# MKW21Z4 register map
Vendor: Freescale Semiconductor, Inc.; Series: Kinetis_W; File version: 1.6
CPU: CM0PLUS r0p0, little endian, no MPU, no FPU, VTOR, 2 interrupt priority bits
Registers are 16-bit, read-write, no defined reset value unless marked. A register's access mark holds for its fields unless they carry their own. Offsets are from the block's base; [hi:lo] are bit positions; {n}, {i} and the like mark numbered series; 'fields as' and 'values as' point back to an identical list.

## ZLL_REGS — ZLL
Base 0x4005D000
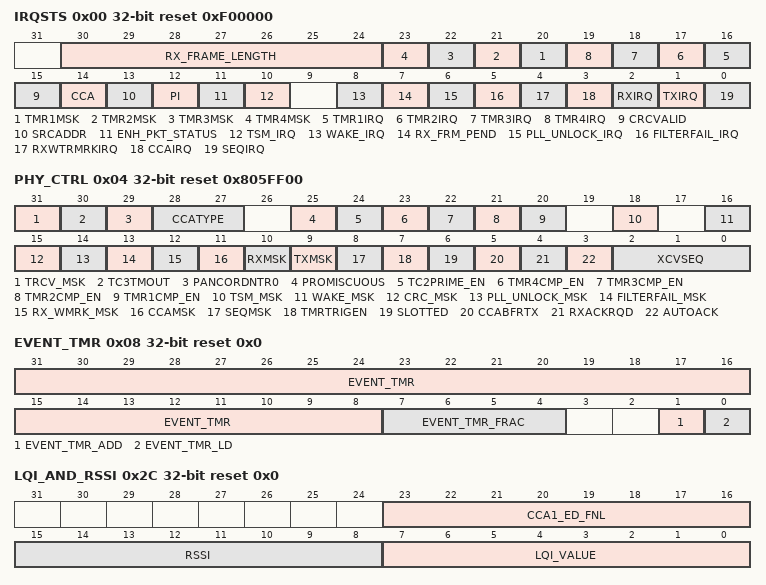
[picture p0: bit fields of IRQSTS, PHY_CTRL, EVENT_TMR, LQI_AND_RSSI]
0x00 IRQSTS 32-bit reset 0xF00000 (reset mask 0x80F00200) — INTERRUPT REQUEST STATUS
  [30:24] RX_FRAME_LENGTH ro — Receive Frame Length
  [n+19] TMR{n}MSK (n=1..4) — Timer Comperator {n} Interrupt Mask bit
    0=allows interrupt when comparator matches event timer count; 1=Interrupt generation is disabled, but a TMR{n}IRQ flag can be set
  [n+15] TMR{n}IRQ (n=1..4) — Timer {n} IRQ
  [15] CRCVALID ro — CRC Valid Status
    0=Rx FCS != calculated CRC (incorrect); 1=Rx FCS = calculated CRC (correct)
  [14] CCA ro — CCA Status
    0=IDLE; 1=BUSY
  [13] SRCADDR ro — Source Address Match Status
  [12] PI ro — Poll Indication
    0=the received packet was not a data request; 1=the received packet was a data request, regardless of whether a Source Address table match occurred, or whether Source Address Management is enabled or not
  [11] ENH_PKT_STATUS ro — Enhanced Packet Status
    0=The last packet received was neither 4e- nor 2015-compliant; 1=The last packet received was 4e- or 2015-compliant (RX_FRAME_FILTER register should be queried for additional status bits)
  [10] TSM_IRQ ro
    0=A TSM Interrupt has not occurred; 1=A TSM Interrupt has occurred
  [8] WAKE_IRQ — WAKE Interrupt Request
    0=A Wake Interrupt has not occurred; 1=A Wake Interrupt has occurred
  [7] RX_FRM_PEND ro — RX Frame Pending
  [6] PLL_UNLOCK_IRQ
    0=A PLL Unlock Interrupt has not occurred; 1=A PLL Unlock Interrupt has occurred
  [5] FILTERFAIL_IRQ
    0=A Filter Fail Interrupt has not occurred; 1=A Filter Fail Interrupt has occurred
  [4] RXWTRMRKIRQ — Receive Watermark IRQ
    0=A Receive Watermark Interrupt has not occurred; 1=A Receive Watermark Interrupt has occurred
  [3] CCAIRQ
    0=A CCA Interrupt has not occurred; 1=A CCA Interrupt has occurred
  [2] RXIRQ
    0=A RX Interrupt has not occurred; 1=A RX Interrupt has occurred
  [1] TXIRQ
    0=A TX Interrupt has not occurred; 1=A TX Interrupt has occurred
  [0] SEQIRQ — Sequencer IRQ
    0=A Sequencer Interrupt has not occurred; 1=A Sequencer Interrupt has occurred
0x04 PHY_CTRL 32-bit reset 0x805FF00 — PHY CONTROL
  [31] TRCV_MSK — Transceiver Global Interrupt Mask
    0=Enable any unmasked interrupt source to assert zigbee interrupt; 1=Mask all interrupt sources from asserting zigbee interrupt
  [30] TC3TMOUT — TMR3 Timeout Enable
    0=TMR3 is a software timer only; 1=Enable TMR3 to abort Rx or CCCA operations
  [29] PANCORDNTR0 — Device is a PAN Coordinator on PAN0
  [28:27] CCATYPE — Clear Channel Assessment Type
    0=ENERGY DETECT; 1=CCA MODE 1; 2=CCA MODE 2; 3=CCA MODE 3
  [25] PROMISCUOUS — Promiscuous Mode Enable
    0=normal mode; 1=all packet filtering except frame length checking (FrameLength>=5 and FrameLength<=127) is bypassed
  [24] TC2PRIME_EN — Timer 2 Prime Compare Enable
    0=Don't allow a match of the lower 16 bits of Event Timer to T2PRIMECMP to set TMR2IRQ; 1=Allow a match of the lower 16 bits of Event Timer to T2PRIMECMP to set TMR2IRQ
  [23] TMR4CMP_EN — Timer 4 Compare Enable
    0=Don't allow an Event Timer Match to T4CMP to set TMR4IRQ; 1=Allow an Event Timer Match to T4CMP to set TMR4IRQ
  [22] TMR3CMP_EN — Timer 3 Compare Enable
    0=Don't allow an Event Timer Match to T3CMP to set TMR3IRQ; 1=Allow an Event Timer Match to T3CMP to set TMR3IRQ
  [21] TMR2CMP_EN — Timer 2 Compare Enable
    0=Don't allow an Event Timer Match to T2CMP or T2PRIMECMP to set TMR2IRQ; 1=Allow an Event Timer Match to T2CMP or T2PRIMECMP to set TMR2IRQ
  [20] TMR1CMP_EN — Timer 1 Compare Enable
    0=Don't allow an Event Timer Match to T1CMP to set TMR1IRQ; 1=Allow an Event Timer Match to T1CMP to set TMR1IRQ
  [18] TSM_MSK
    0=allows assertion of a TSM interrupt to generate a zigbee interrupt; 1=Assertion of a TSM interrupt will set the TSM_IRQ status bit, but a zigbee interrupt is not generated
  [16] WAKE_MSK
    0=Allows a wakeup from DSM to generate a zigbee interrupt; 1=Wakeup from DSM will set the WAKE_IRQ status bit, but a zigbee interrupt is not generated
  [15] CRC_MSK — CRC Mask
    0=sequence manager ignores CRCVALID and considers the receive operation complete after the last octet of the frame has been received; 1=sequence manager requires CRCVALID=1 at the end of the received frame in order for the receive operation to complete successfully; if CRCVALID=0, sequence manager will return to preamble-detect mode after the last octet of the frame has been received
  [14] PLL_UNLOCK_MSK — PLL Unlock Interrupt Mask
    0=allows PLL unlock event to generate a zigbee interrupt; 1=A PLL unlock event will set the PLL_UNLOCK_IRQ status bit, but a zigbee interrupt is not generated
  [13] FILTERFAIL_MSK — FilterFail Interrupt Mask
    0=allows Packet Processor Filtering Failure to generate a zigbee interrupt; 1=A Packet Processor Filtering Failure will set the FILTERFAIL_IRQ status bit, but a zigbee interrupt is not generated
  [12] RX_WMRK_MSK — RX Watermark Interrupt Mask
    0=allows a Received Byte Count match to the RX_WTR_MARK threshold register to generate a zigbee interrupt; 1=A Received Byte Count match to the RX_WTR_MARK threshold register will set the RXWTRMRKIRQ status bit, but a zigbee interrupt is not generated
  [11] CCAMSK — CCA Interrupt Mask
    0=allows completion of a CCA operation to generate a zigbee interrupt; 1=Completion of a CCA operation will set the CCA status bit, but a zigbee interrupt is not generated
  [10] RXMSK — RX Interrupt Mask
    0=allows completion of a RX operation to generate a zigbee interrupt; 1=Completion of a RX operation will set the RXIRQ status bit, but a zigbee interrupt is not generated
  [9] TXMSK — TX Interrupt Mask
    0=allows completion of a TX operation to generate a zigbee interrupt; 1=Completion of a TX operation will set the TXIRQ status bit, but a zigbee interrupt is not generated
  [8] SEQMSK — Sequencer Interrupt Mask
    0=allows completion of an autosequence to generate a zigbee interrupt; 1=Completion of an autosequence will set the SEQIRQ status bit, but a zigbee interrupt is not generated
  [7] TMRTRIGEN — Timer2 Trigger Enable
    0=programmed sequence initiates immediately upon write to XCVSEQ; 1=allow timer TC2 (or TC2') to initiate a preprogrammed sequence (see XCVSEQ register)
  [6] SLOTTED — Slotted Mode
  [5] CCABFRTX — CCA Before TX
    0=no CCA required, transmit operation begins immediately; 1=at least one CCA measurement is required prior to the transmit operation (see also SLOTTED)
  [4] RXACKRQD — Receive Acknowledge Frame required
    0=An ordinary receive frame (any type of frame) follows the transmit frame; 1=A receive Ack frame is expected to follow the transmit frame (non-Ack frames are rejected)
  [3] AUTOACK — Auto Acknowledge Enable
    0=sequence manager will not follow a receive frame with a Tx Ack frame, under any conditions; the autosequence will terminate after the receive frame; 1=sequence manager will follow a receive frame with an automatic hardware-generated Tx Ack frame, assuming other necessary conditions are met
  [2:0] XCVSEQ — Zigbee Transceiver Sequence Selector
    0=I (IDLE); 1=R (RECEIVE); 2=T (TRANSMIT); 3=C (CCA); 4=TR (TRANSMIT/RECEIVE); 5=CCCA (CONTINUOUS CCA)
0x08 EVENT_TMR 32-bit reset 0x0 (reset mask 0xF) — EVENT TIMER
  [31:8] EVENT_TMR — Event Timer Integer Component
  [7:4] EVENT_TMR_FRAC — Event Timer Fractional Component
  [1] EVENT_TMR_ADD wo — Event Timer Add Enable
  [0] EVENT_TMR_LD wo — Event Timer Load Enable
0x0C TIMESTAMP 32-bit ro reset 0x0 (reset mask 0xFF000000)
  [23:0] TIMESTAMP
0x10 T1CMP 32-bit reset 0xFFFFFF — T1 COMPARE
  [23:0] T1CMP — TMR1 Compare Value
0x14 T2CMP 32-bit reset 0xFFFFFF — T2 COMPARE
  [23:0] T2CMP — TMR2 Compare Value
0x18 T2PRIMECMP 32-bit reset 0xFFFF — T2 PRIME COMPARE
  [15:0] T2PRIMECMP — TMR2 Prime Compare Value
0x1C T3CMP 32-bit reset 0xFFFFFF — T3 COMPARE
  [23:0] T3CMP — TMR3 Compare Value
0x20 T4CMP 32-bit reset 0xFFFFFF — T4 COMPARE
  [23:0] T4CMP — TMR4 Compare Value
0x24 PA_PWR 32-bit reset 0x0 — PA POWER
  [5:0] PA_PWR — PA Power
0x28 CHANNEL_NUM0 32-bit reset 0x12 — CHANNEL NUMBER 0
  [6:0] CHANNEL_NUM0 — Channel Number for PAN0
0x2C LQI_AND_RSSI 32-bit ro reset 0x0 (reset mask 0xFF000000)
  [23:16] CCA1_ED_FNL — Final Result for CCA Mode 1 and Energy Detect
  [15:8] RSSI — RSSI Value
  [7:0] LQI_VALUE
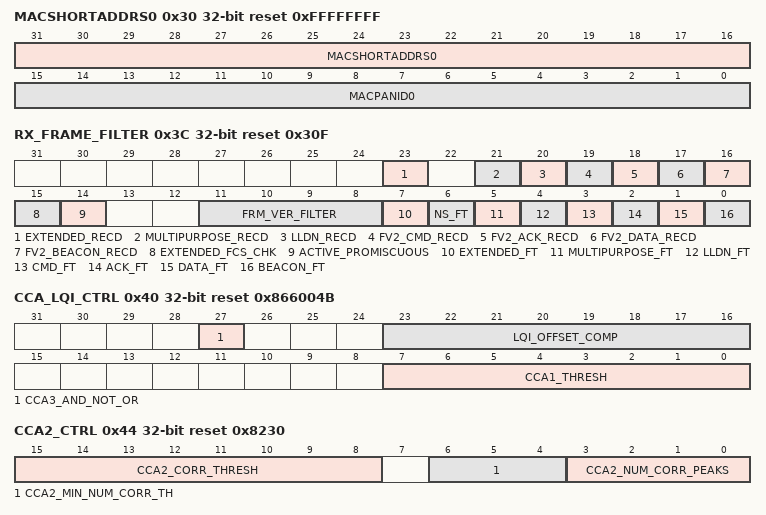
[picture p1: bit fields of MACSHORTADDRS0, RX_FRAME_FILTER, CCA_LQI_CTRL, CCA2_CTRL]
0x30 MACSHORTADDRS0 32-bit reset 0xFFFFFFFF — MAC SHORT ADDRESS 0
  [31:16] MACSHORTADDRS0 — MAC SHORT ADDRESS FOR PAN0
  [15:0] MACPANID0 — MAC PAN ID for PAN0
0x34 MACLONGADDRS0_LSB 32-bit reset 0xFFFFFFFF — MAC LONG ADDRESS 0 LSB
  [31:0] MACLONGADDRS0_LSB — MAC LONG ADDRESS for PAN0 LSB
0x38 MACLONGADDRS0_MSB 32-bit reset 0xFFFFFFFF — MAC LONG ADDRESS 0 MSB
  [31:0] MACLONGADDRS0_MSB — MAC LONG ADDRESS for PAN0 MSB
0x3C RX_FRAME_FILTER 32-bit reset 0x30F (reset mask 0xFF40FFFF) — RECEIVE FRAME FILTER
  [23] EXTENDED_RECD ro — Extended Packet Received
    0=The last packet received was not Frame Type EXTENDED; 1=The last packet received was Frame Type EXTENDED, and EXTENDED_FT=1 to allow such packets
  [21] MULTIPURPOSE_RECD ro — Multipurpose Packet Received
    0=last packet received was not Frame Type MULTIPURPOSE; 1=The last packet received was Frame Type MULTIPURPOSE, and MULTIPURPOSE_FT=1 to allow such packets
  [20] LLDN_RECD ro — LLDN Packet Received
    0=The last packet received was not Frame Type LLDN; 1=The last packet received was Frame Type LLDN, and LLDN_FT=1 to allow such packets
  [19] FV2_CMD_RECD ro — Frame Version 2 MAC Command Packet Received
    0=The last packet received was not Frame Type MAC Command with Frame Version 2; 1=The last packet received was Frame Type MAC Command with Frame Version 2, and FRM_VER_FILTER[2]=1 to allow such packets
  [18] FV2_ACK_RECD ro — Frame Version 2 Acknowledge Packet Received
    0=The last packet received was not Frame Type Ack with Frame Version 2; 1=The last packet received was Frame Type Ack with Frame Version 2, and FRM_VER_FILTER[2]=1 to allow such packets
  [17] FV2_DATA_RECD ro — Frame Version 2 Data Packet Received
    0=The last packet received was not Frame Type Data with Frame Version 2; 1=The last packet received was Frame Type Data with Frame Version 2, and FRM_VER_FILTER[2]=1 to allow such packets
  [16] FV2_BEACON_RECD ro — Frame Version 2 Beacon Packet Received
    0=The last packet received was not Frame Type Beacon with Frame Version 2; 1=The last packet received was Frame Type Beacon with Frame Version 2, and FRM_VER_FILTER[2]=1 to allow such packets
  [15] EXTENDED_FCS_CHK — Verify FCS on Frame Type Extended
    0=Packet Processor will not check FCS for Frame Type EXTENDED (default); 1=Packet Processor will check FCS at end-of-packet based on packet length derived from PHR, for Frame Type EXTENDED
  [14] ACTIVE_PROMISCUOUS
    0=normal operation; 1=Provide Data Indication on all received packets under the same rules which apply in PROMISCUOUS mode, however acknowledge those packets under rules which apply in non-PROMISCUOUS mode
  [11:8] FRM_VER_FILTER — Frame Version selector.
  [7] EXTENDED_FT — Extended Frame Type Enable
    0=reject all Extended frames; 1=Extended frame type enabled (Frame Type 7)
  [6] NS_FT — "Not Specified" Frame Type Enable
    0=reject all "Not Specified" frames; 1=Not-specified (reserved) frame type enabled. Applies to Frame Type 6. No packet filtering is performed, except for frame length checking (FrameLength>=5 and FrameLength<=127). No AUTOACK is transmitted for this Frame Type
  [5] MULTIPURPOSE_FT — Multipurpose Frame Type Enable
    0=reject all Multipurpose frames; 1=Multipurpose frame type enabled (Frame Type 5)
  [4] LLDN_FT — LLDN Frame Type Enable
    0=reject all LLDN frames; 1=LLDN frame type enabled (Frame Type 4)
  [3] CMD_FT — MAC Command Frame Type Enable
    0=reject all MAC Command frames; 1=MAC Command frame type enabled
  [2] ACK_FT — Ack Frame Type Enable
    0=reject all Acknowledge frames; 1=Acknowledge frame type enabled
  [1] DATA_FT — Data Frame Type Enable
    0=reject all Beacon frames; 1=Data frame type enabled
  [0] BEACON_FT — Beacon Frame Type Enable
    0=reject all Beacon frames; 1=Beacon frame type enabled
0x40 CCA_LQI_CTRL 32-bit reset 0x866004B — CCA AND LQI CONTROL
  [27] CCA3_AND_NOT_OR — CCA Mode 3 AND not OR
    0=CCA1 or CCA2; 1=CCA1 and CCA2
  [23:16] LQI_OFFSET_COMP — LQI Offset Compensation
  [7:0] CCA1_THRESH — CCA Mode 1 Threshold
0x44 CCA2_CTRL 32-bit reset 0x8230 (reset mask 0xFFFFFFF0) — CCA2 CONTROL
  [15:8] CCA2_CORR_THRESH — CCA Mode 2 Correlation Threshold
  [6:4] CCA2_MIN_NUM_CORR_TH — CCA Mode 2 Threshold Number of Correlation Peaks
  [3:0] CCA2_NUM_CORR_PEAKS ro — CCA Mode 2 Number of Correlation Peaks Detected
0x4C DSM_CTRL 32-bit reset 0x0 — DSM CONTROL
  [0] ZIGBEE_SLEEP_EN — Zigbee sleep enable
0x50 BSM_CTRL 32-bit reset 0x0 — BSM CONTROL
  [0] BSM_EN — BSM Enable
    0=Zigbee Bit Streaming Mode Disabled; 1=Zigbee Bit Streaming Mode Enabled
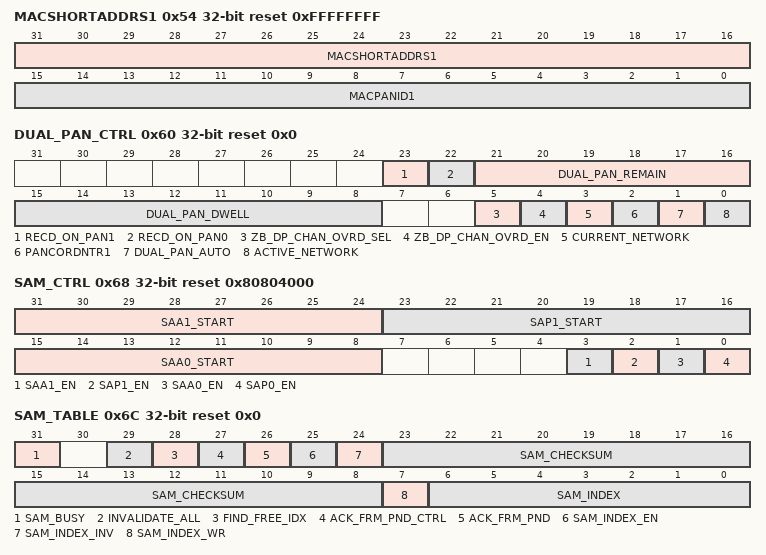
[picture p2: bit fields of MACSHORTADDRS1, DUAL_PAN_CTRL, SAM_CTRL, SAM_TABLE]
0x54 MACSHORTADDRS1 32-bit reset 0xFFFFFFFF — MAC SHORT ADDRESS FOR PAN1
  [31:16] MACSHORTADDRS1 — MAC SHORT ADDRESS for PAN1
  [15:0] MACPANID1 — MAC PAN ID for PAN1
0x58 MACLONGADDRS1_LSB 32-bit reset 0xFFFFFFFF — MAC LONG ADDRESS 1 LSB
  [31:0] MACLONGADDRS1_LSB — MAC LONG ADDRESS for PAN1 LSB
0x5C MACLONGADDRS1_MSB 32-bit reset 0xFFFFFFFF — MAC LONG ADDRESS 1 MSB
  [31:0] MACLONGADDRS1_MSB — MAC LONG ADDRESS for PAN1 MSB
0x60 DUAL_PAN_CTRL 32-bit reset 0x0 (reset mask 0xFF00FFF7) — DUAL PAN CONTROL
  [23] RECD_ON_PAN1 ro — Last Packet was Received on PAN1
  [22] RECD_ON_PAN0 ro — Last Packet was Received on PAN0
  [21:16] DUAL_PAN_REMAIN ro — Time Remaining before next PAN switch in auto Dual PAN mode
  [15:8] DUAL_PAN_DWELL — Dual PAN Channel Frequency Dwell Time
  [5] ZB_DP_CHAN_OVRD_SEL — Dual PAN Channel Override Selector
  [4] ZB_DP_CHAN_OVRD_EN — Dual PAN Channel Override Enable
  [3] CURRENT_NETWORK ro — Indicates which PAN is currently selected by hardware
    0=PAN0 is selected; 1=PAN1 is selected
  [2] PANCORDNTR1 — Device is a PAN Coordinator on PAN1
  [1] DUAL_PAN_AUTO — Activates automatic Dual PAN operating mode
  [0] ACTIVE_NETWORK — Active Network Selector
    0=Select PAN0; 1=Select PAN1
0x64 CHANNEL_NUM1 32-bit reset 0x7F — CHANNEL NUMBER 1
  [6:0] CHANNEL_NUM1 — Channel Number for PAN1
0x68 SAM_CTRL 32-bit reset 0x80804000 — SAM CONTROL
  [31:24] SAA1_START — First Index of SAA1 partition
  [23:16] SAP1_START — First Index of SAP1 partition
  [15:8] SAA0_START — First Index of SAA0 partition
  [3] SAA1_EN — Enables SAA1 Partition of the SAM Table
    0=Disables SAA1 Partition; 1=Enables SAA1 Partition
  [2] SAP1_EN — Enables SAP1 Partition of the SAM Table
    0=Disables SAP1 Partition; 1=Enables SAP1 Partition
  [1] SAA0_EN — Enables SAA0 Partition of the SAM Table
    0=Disables SAA0 Partition; 1=Enables SAA0 Partition
  [0] SAP0_EN — Enables SAP0 Partition of the SAM Table
    0=Disables SAP0 Partition; 1=Enables SAP0 Partition
0x6C SAM_TABLE 32-bit reset 0x0 (reset mask 0x4C00007F) — SOURCE ADDRESS MANAGEMENT TABLE
  [31] SAM_BUSY ro — SAM Table Update Status Bit
  [29] INVALIDATE_ALL wo — Invalidate Entire SAM Table
  [28] FIND_FREE_IDX wo — Find First Free Index
  [27] ACK_FRM_PND_CTRL — Manual Control for AutoTxAck FramePending field
    0=the FramePending field of the Frame Control Field of the next automatic TX acknowledge packet is determined by hardware; 1=the FramePending field of the Frame Control Field of the next automatic TX acknowledge packet tracks ACK_FRM_PEND
  [26] ACK_FRM_PND — State of AutoTxAck FramePending field when SAM Accelleration is Disabled
  [25] SAM_INDEX_EN wo — Enable the SAM table index selected by SAM_INDEX
  [24] SAM_INDEX_INV wo — Invalidate the SAM table index selected by SAM_INDEX
  [23:8] SAM_CHECKSUM — Software-computed source address checksum, to be installed into a table index
  [7] SAM_INDEX_WR wo — Enables SAM Table Contents to be updated
  [6:0] SAM_INDEX — Contains the SAM table index to be enabled or invalidated
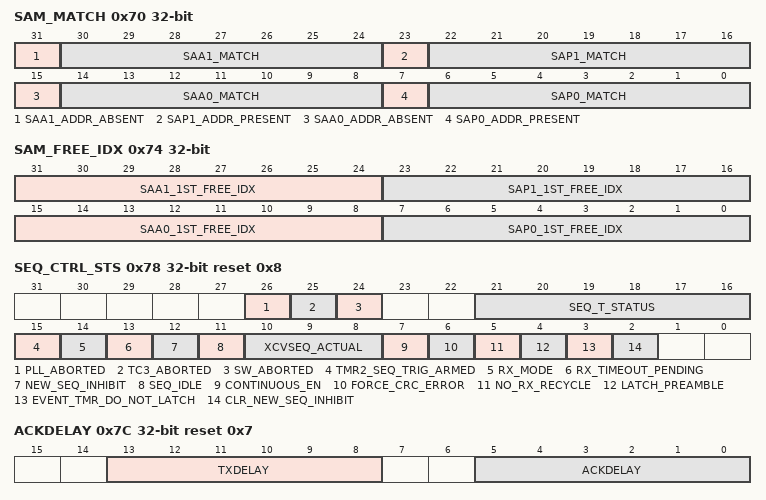
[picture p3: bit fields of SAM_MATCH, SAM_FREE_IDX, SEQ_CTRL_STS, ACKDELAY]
0x70 SAM_MATCH 32-bit ro — SOURCE ADDRESS MANAGEMENT MATCH
  [31] SAA1_ADDR_ABSENT — A Checksum Match is Absent in the SAP1 Partition of the SAM Table
  [30:24] SAA1_MATCH — Index in the SAA1 Partition of the SAM Table corresponding to the first checksum match
  [23] SAP1_ADDR_PRESENT — A Checksum Match is Present in the SAP1 Partition of the SAM Table
  [22:16] SAP1_MATCH — Index in the SAP1 Partition of the SAM Table corresponding to the first checksum match
  [15] SAA0_ADDR_ABSENT — A Checksum Match is Absent in the SAA0 Partition of the SAM Table
  [14:8] SAA0_MATCH — Index in the SAA0 Partition of the SAM Table corresponding to the first checksum match
  [7] SAP0_ADDR_PRESENT — A Checksum Match is Present in the SAP0 Partition of the SAM Table
  [6:0] SAP0_MATCH — Index in the SAP0 Partition of the SAM Table corresponding to the first checksum match
0x74 SAM_FREE_IDX 32-bit ro — SAM FREE INDEX
  [31:24] SAA1_1ST_FREE_IDX — First non-enabled (invalid) index in the SAA1 partition
  [23:16] SAP1_1ST_FREE_IDX — First non-enabled (invalid) index in the SAP1 partition
  [15:8] SAA0_1ST_FREE_IDX — First non-enabled (invalid) index in the SAA0 partition
  [7:0] SAP0_1ST_FREE_IDX — First non-enabled (invalid) index in the SAP0 partition
0x78 SEQ_CTRL_STS 32-bit reset 0x8 (reset mask 0xF8C000FF) — SEQUENCE CONTROL AND STATUS
  [26] PLL_ABORTED ro — Autosequence has terminated due to an PLL unlock event
  [25] TC3_ABORTED ro — autosequence has terminated due to an TMR3 timeout
  [24] SW_ABORTED ro — Autosequence has terminated due to a Software abort.
  [21:16] SEQ_T_STATUS ro — Status of the just-completed or ongoing Sequence T or Sequence TR
  [15] TMR2_SEQ_TRIG_ARMED ro — indicates that TMR2 has been programmed and is armed to trigger a new autosequence
  [14] RX_MODE ro — RX Operation in Progress
  [13] RX_TIMEOUT_PENDING ro — Indicates a TMR3 RX Timeout is Pending
  [12] NEW_SEQ_INHIBIT ro — New Sequence Inhibit
  [11] SEQ_IDLE ro — ZSM Sequence Idle Indicator
  [10:8] XCVSEQ_ACTUAL ro — Indicates the programmed sequence that has been recognized by the ZSM Sequence Manager
  [7] CONTINUOUS_EN — Enable Continuous TX or RX Mode
    0=normal operation; 1=Continuous TX or RX mode is enabled (depending on XCVSEQ setting)
  [6] FORCE_CRC_ERROR — Induce a CRC Error in Transmitted Packets
    0=normal operation; 1=Force the next transmitted packet to have a CRC error
  [5] NO_RX_RECYCLE — Disable Automatic RX Sequence Recycling
  [4] LATCH_PREAMBLE — Stickiness Control for Preamble Detection
    0=Don't make PREAMBLE_DET and SFD_DET bits of PHY_STS (SEQ_STATE) Register "sticky", i.e, these status bits reflect the realtime, dynamic state of preamble_detect and sfd_detect; 1=Make PREAMBLE_DET and SFD_DET bits of PHY_STS (SEQ_STATE) Register "sticky", i.e.,occurrences of preamble and SFD detection are latched and held until the start of the next autosequence
  [3] EVENT_TMR_DO_NOT_LATCH — Overrides the automatic hardware latching of the Event Timer
  [2] CLR_NEW_SEQ_INHIBIT — Overrides the automatic hardware locking of the programmed XCVSEQ while an autosequence is underway
0x7C ACKDELAY 32-bit reset 0x7
  [13:8] TXDELAY, [5:0] ACKDELAY
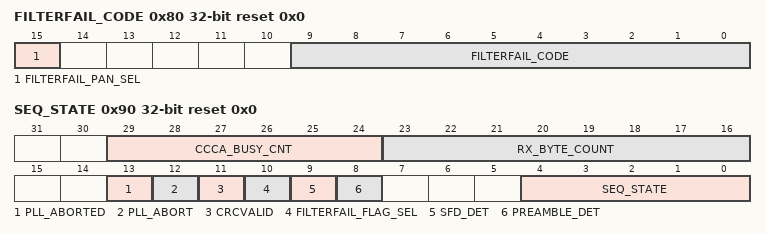
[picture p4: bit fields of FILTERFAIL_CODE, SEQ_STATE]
0x80 FILTERFAIL_CODE 32-bit reset 0x0 (reset mask 0xFFFFFC00)
  [15] FILTERFAIL_PAN_SEL — PAN Selector for Filter Fail Code
    0=FILTERFAIL_CODE[9:0] will report the FILTERFAIL status of PAN0; 1=FILTERFAIL_CODE[9:0] will report the FILTERFAIL status of PAN1
  [9:0] FILTERFAIL_CODE ro
0x84 RX_WTR_MARK 32-bit reset 0xFF — RECEIVE WATER MARK
  [7:0] RX_WTR_MARK
0x8C SLOT_PRELOAD 32-bit reset 0x74
  [7:0] SLOT_PRELOAD — Slotted Mode Preload
0x90 SEQ_STATE 32-bit ro reset 0x0 (reset mask 0xC000C0E0) — 802.15.4 SEQUENCE STATE
  [29:24] CCCA_BUSY_CNT — Number of CCA Measurements resulting in Busy Channel
  [23:16] RX_BYTE_COUNT — Realtime Received Byte Count
  [13] PLL_ABORTED — Autosequence has terminated due to an PLL unlock event
  [12] PLL_ABORT — Raw PLL Abort Signal
  [11] CRCVALID — CRC Valid Indicator
    values as IRQSTS.CRCVALID
  [10] FILTERFAIL_FLAG_SEL — Consolidated Filter Fail Flag
  [9] SFD_DET — SFD Detected
  [8] PREAMBLE_DET — Preamble Detected
  [4:0] SEQ_STATE — ZSM Sequence State
0x94 TMR_PRESCALE 32-bit reset 0x5 — TIMER PRESCALER
  [2:0] TMR_PRESCALE — Timer Prescaler
    2=500kHz (33.55 S); 3=250kHz (67.11 S); 4=125kHz (134.22 S); 5=62.5kHz (268.44 S) -- default; 6=31.25kHz (536.87 S); 7=15.625kHz (1073.74 S)
0x98 LENIENCY_LSB 32-bit reset 0x0
0x9C LENIENCY_MSB 32-bit reset 0x0
  [7:0] LENIENCY_MSB
0xA0 PART_ID 32-bit ro reset 0x2
  [7:0] PART_ID — 802.15.4 Part ID
{0x100+2i} PKT_BUFFER_TX{i} (i=0..63) — Packet Buffer TX
  [15:0] PKT_BUFFER_TX — Packet Buffer Entry
{0x180+2i} PKT_BUFFER_RX{i} (i=0..63) — Packet Buffer RX
  [15:0] PKT_BUFFER_RX — Packet Buffer Entry
